# SIM3L166_C register map
File version: 1
CPU: 
Registers are 32-bit, read-write, reset 0x0 unless marked. A register's access mark holds for its fields unless they carry their own. Offsets are from the block's base; [hi:lo] are bit positions; 'fields as' and 'values as' point back to an identical list.

## TIMER_0
Base 0x40014000
Same registers: TIMER_1 0x40015000, TIMER_2 0x40016000
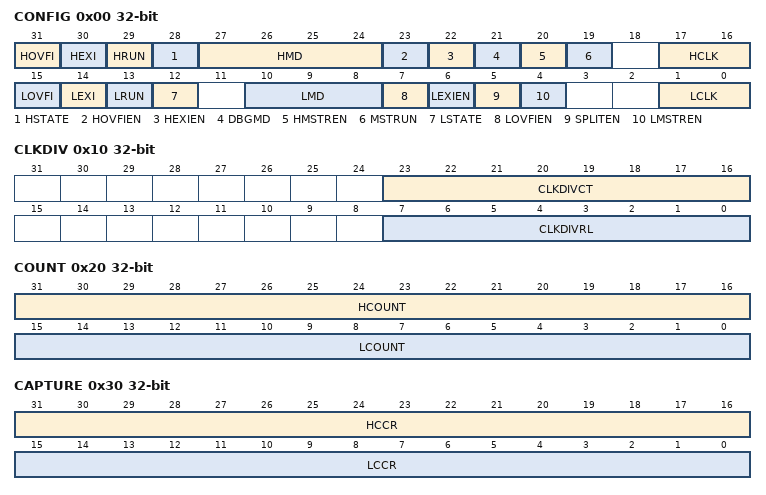
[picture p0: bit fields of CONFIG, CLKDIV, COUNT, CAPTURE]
0x00 CONFIG — High and Low Timer Configuration
  [31] HOVFI — High Timer Overflow Interrupt Flag.
    0=NOT_SET (Read: A high timer overflow interrupt is not pending. Write: Clear the interrupt.); 1=SET (Read: If split mode is enabled (SPLITEN = 1), this value indicates the high 16-bit timer has wrapped or reloaded after reaching all 1's. If split mode is disabled (SPLITEN = 0), this value indicates the 32-bit timer has wrapped or reloaded after reaching all 1's. The timer module can set this bit in all modes. Write: Force a high timer overflow interrupt.)
  [30] HEXI — High Timer Extra Interrupt Flag.
    0=NOT_SET (Read: A high timer extra interrupt is not pending. Write: Clear the interrupt.); 1=SET (Read: Indicates the high 16-bit timer (or 32-bit timer if SPLITEN = 0) has been captured, reloaded with all 1's when counting down, or the timer matched the capture register in PWM mode. This interrupt flag can be set by the timer module in all modes except Auto-Reload and Toggle. Write: Force a high timer extra interrupt.)
  [29] HRUN — High Run Control.
    0=STOP (Stop the high timer or entire 32-bit timer.); 1=START (The high timer runs if HMSTREN = 0 or MSTRUN (in Timer 0) = 1. The full 32-bit timer runs if split mode is disabled and (HMSTREN = 0 or MSTRUN = 1).)
  [28] HSTATE — High Multi Purpose State Indicator.
    0=NOT_SET; 1=SET
  [27:24] HMD — High Timer Mode.
    0=AUTO_RELOAD (The high 16-bit timer or entire 32-bit timer is in Auto-Reload Mode.); 1=UP_DOWN (The high 16-bit timer or entire 32-bit timer is in Up/Down Count Mode.); 2=FALL_CAPTURE (The high 16-bit timer or entire 32-bit timer is in Falling Edge Capture Mode.); 3=RISE_CAPTURE (The high 16-bit timer or entire 32-bit timer is in Rising Edge Capture Mode.); 4=LOW_CAPTURE (The high 16-bit timer or entire 32-bit timer is in Low Time Capture Mode.); 5=HIGH_CAPTURE (The high 16-bit timer or entire 32-bit timer is in High Time Capture Mode.); 6=DC_CAPTURE (The high 16-bit timer or entire 32-bit timer is in Duty Cycle Capture Mode.); 7=ONESHOT (The high 16-bit timer or entire 32-bit timer is in Oneshot Mode.); 8=TOGGLE (The high 16-bit timer or entire 32-bit timer is in Square Wave Output Mode.); 9=PWM (The high 16-bit timer or entire 32-bit timer is in PWM Mode.)
  [23] HOVFIEN — High Timer Overflow Interrupt Enable.
    0=DISABLED (The state of HOVFI does not affect the high timer interrupt.); 1=ENABLED (A high timer interrupt request is generated if HOVFI is set to 1.)
  [22] HEXIEN — High Timer Extra Interrupt Enable.
    0=DISABLED (The state of the HEXI flag does not affect the high timer interrupt.); 1=ENABLED (A high timer interrupt request is generated if HEXI is set to 1.)
  [21] DBGMD — Timer Debug Mode.
    0=RUN (The timer will continue to operate while the core is halted in debug mode.); 1=HALT (A debug breakpoint will cause the Timer to halt.)
  [20] HMSTREN — High Master Enable.
    0=DISABLED (MSTRUN does not need to be set for the timer to run.); 1=ENABLED (MSTRUN must be set for the timer to run.)
  [19] MSTRUN — Master Run Control.
    0=STOP (Disable the master run control for all timers.); 1=START (Enable the master run control for all timers.)
  [17:16] HCLK — High Clock Source.
    0=APB (Select the APB clock as the timer source.); 1=EXTOSCN (Select the external oscillator clock as the timer source. The external oscillator must run slower than one-half the APB clock.); 2=TIMER_CLKDIV (Select the dedicated 8-bit prescaler as the timer source.); 3=CT_FALLING_EDGE (Select falling edges of the CT signal as the timer clock source.)
  [15] LOVFI — Low Timer Overflow Interrupt.
    0=NOT_SET (Read: A low timer overflow interrupt is not pending. Write: Clear the interrupt.); 1=SET (Read: The low 16-bit timer has wrapped or reloaded after reaching all 1's. This bit is set by the module regardless of the state of SPLITEN and can be set in all modes. Write: Force a low timer overflow interrupt.)
  [14] LEXI — Low Timer Extra Interrupt Flag.
    0=NOT_SET (Read: A low timer extra interrupt is not pending. Write: Clear the interrupt.); 1=SET (Read: Indicates the low 16-bit timer has been captured, reloaded with all 1's when counting down, or the timer matched the capture register in PWM mode. This interrupt flag can be set by hardware in all modes except Auto-Reload and Toggle. This flag is not set by hardware when split mode is disabled (SPLITEN = 0). Write: Force a low timer extra interrupt.)
  [13] LRUN — Run Control Low.
    0=STOP (Stop the low timer if split mode is enabled (SPLITEN = 1).); 1=START (The low timer runs if split mode is enabled (SPLITEN = 1) and (LMSTREN = 0 or MSTRUN = 1 in Timer 0).)
  [12] LSTATE — Low Multi Purpose State Indicator.
    0=NOT_SET; 1=SET
  [10:8] LMD — Low Timer Mode.
    0=AUTO_RELOAD (The low timer is in Auto-Reload Mode.); 1=UP_DOWN (The low timer is in Up/Down Count Mode.); 2=FALL_CAPTURE (The low timer is in Falling Edge Capture Mode.); 3=RISE_CAPTURE (The low timer is in Rising Edge Capture Mode.); 4=LOW_CAPTURE (The low timer is in Low Time Capture Mode.); 5=HIGH_CAPTURE (The low timer is in High Time Capture Mode.); 6=DC_CAPTURE (The low timer is in Duty Cycle Capture Mode.); 7=ONESHOT (The low timer is in Oneshot Mode.)
  [7] LOVFIEN — Low Timer Overflow Interrupt Enable.
    0=DISABLED (The state of LOVFI does not affect the low timer interrupt.); 1=ENABLED (A low timer interrupt request is generated if LOVFI = 1.)
  [6] LEXIEN — Low Timer Extra Interrupt Enable.
    0=DISABLED (The state of the LEXI flag does not affect the low timer interrupt.); 1=ENABLED (A low timer interrupt request is generated if LEXI is set to 1.)
  [5] SPLITEN — Split Mode Enable.
    0=DISABLED (The timer operates as a single 32-bit timer controlled by the high timer fields.); 1=ENABLED (The timer operates as two independent 16-bit timers.)
  [4] LMSTREN — Low Run Master Enable.
    0=DISABLED (MSTRUN does not need to be set for the low timer to run.); 1=ENABLED (MSTRUN must be set for the low timer to run.)
  [1:0] LCLK — Low Clock Source.
    values as HCLK
0x10 CLKDIV — Module Clock Divider Control
  [23:16] CLKDIVCT — Clock Divider Counter.
  [7:0] CLKDIVRL — Clock Divider Reload Value.
0x20 COUNT — Timer Value
  [31:16] HCOUNT — High Timer Count.
  [15:0] LCOUNT — Low Timer Count.
0x30 CAPTURE — Timer Capture/Reload Value
  [31:16] HCCR — High Timer Capture/Reload.
  [15:0] LCCR — Low Timer Capture/Reload.
